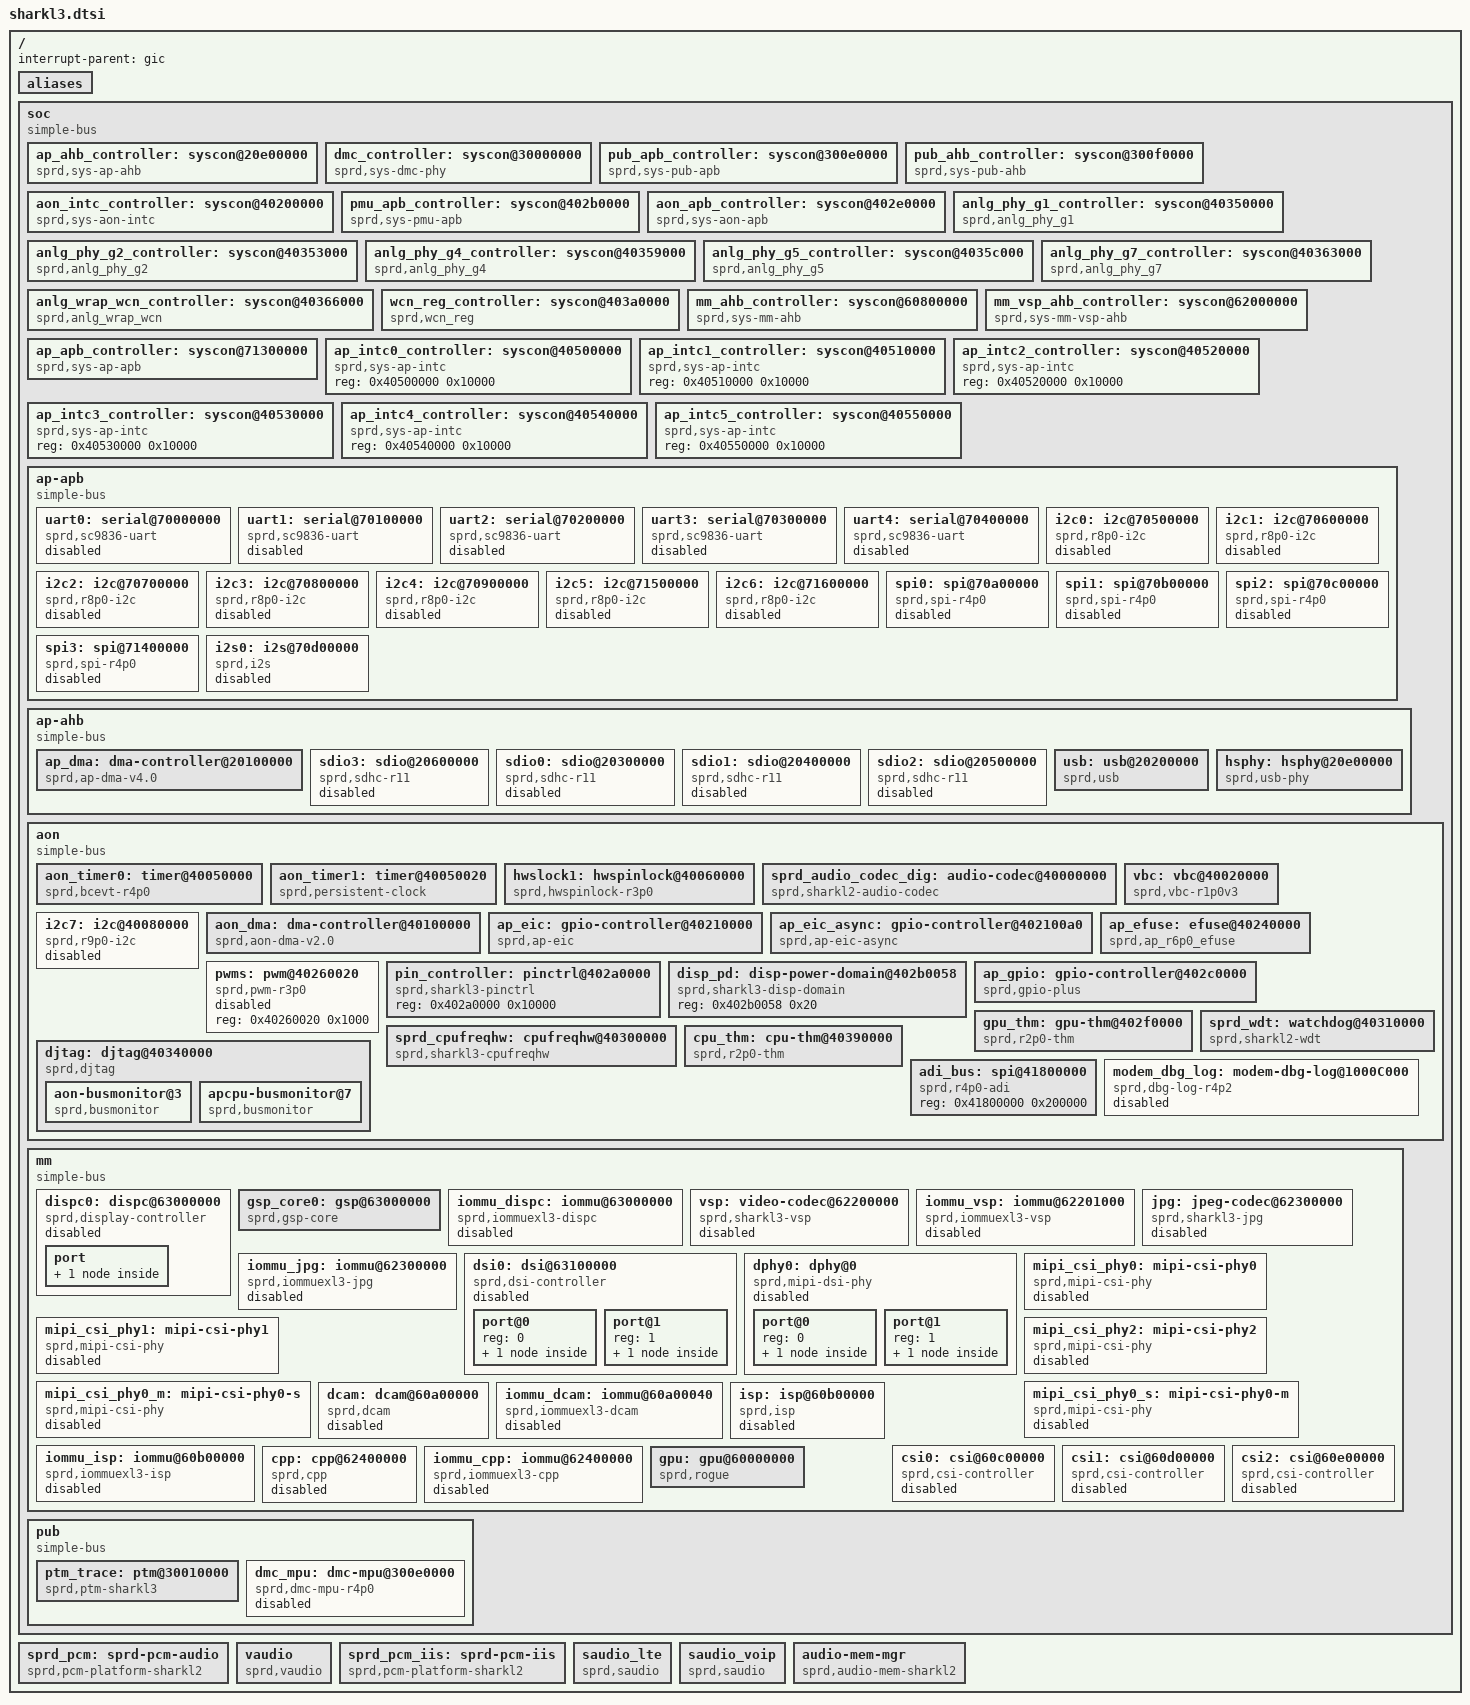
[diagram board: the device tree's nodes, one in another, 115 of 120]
/*
 * Spreadtrum Sharkl3 platform DTS file
 *
 * Copyright (C) 2017, Spreadtrum Communications Inc.
 *
 * This file is licensed under a dual GPLv2 or X11 license.
 */

#include <dt-bindings/debug/busmonitor.h>
#include <dt-bindings/interrupt-controller/arm-gic.h>
#include <dt-bindings/dmc_mpu/sharkl3_dmc_mpu.h>

/ {
	interrupt-parent = <&gic>;
	#address-cells = <1>;
	#size-cells = <1>;

	aliases {
		serial0 = &uart0;
		serial1 = &uart1;
		serial2 = &uart2;
		serial3 = &uart3;
		i2c0 = &i2c0;
		i2c1 = &i2c1;
		i2c2 = &i2c2;
		i2c3 = &i2c3;
		i2c4 = &i2c4;
		i2c5 = &i2c5;
		i2c6 = &i2c6;
		i2c7 = &i2c7;
		spi0 = &spi0;
		spi1 = &spi1;
		spi2 = &spi2;
		spi3 = &spi3;
		hwspinlock1 = &hwslock1;
		thm-sensor0 = &gpu_thm;
		thm-sensor1 = &cpu_thm;
	};

	soc: soc {
		compatible = "simple-bus";
		#address-cells = <1>;
		#size-cells = <1>;
		ranges;

		ap_ahb_controller: syscon@20e00000 {
			compatible = "sprd,sys-ap-ahb", "syscon";
			reg = <0x20e00000 0x10000>;
			hwlocks = <&hwslock1 1>;
			hwlock-names = "syscon";
		};

		dmc_controller: syscon@30000000 {
			compatible = "sprd,sys-dmc-phy", "syscon";
			reg = <0x30000000 0x400>;
			sprd,sizel_off = <0x1c4>;
			sprd,sizeh_off = <0x1c8>;
		};

		pub_apb_controller: syscon@300e0000 {
			compatible = "sprd,sys-pub-apb", "syscon";
			reg = <0x300e0000 0x10000>;
			hwlocks = <&hwslock1 1>;
			hwlock-names = "syscon";
		};

		pub_ahb_controller: syscon@300f0000 {
			compatible = "sprd,sys-pub-ahb", "syscon";
			reg = <0x300f0000 0x10000>;
			hwlocks = <&hwslock1 1>;
			hwlock-names = "syscon";
		};

		aon_intc_controller: syscon@40200000 {
			compatible = "sprd,sys-aon-intc", "syscon";
			reg = <0x40200000 0x10000>;
			hwlocks = <&hwslock1 1>;
			hwlock-names = "syscon";
		};

		pmu_apb_controller: syscon@402b0000 {
			compatible = "sprd,sys-pmu-apb", "syscon";
			reg = <0x402b0000 0x10000>;
			hwlocks = <&hwslock1 1>;
			hwlock-names = "syscon";
		};

		aon_apb_controller: syscon@402e0000 {
			compatible = "sprd,sys-aon-apb", "syscon";
			reg = <0x402e0000 0x10000>;
			hwlocks = <&hwslock1 1>;
			hwlock-names = "syscon";
		};

		anlg_phy_g1_controller: syscon@40350000 {
			compatible = "sprd,anlg_phy_g1", "syscon";
			reg = <0x40350000 0x3000>;
			hwlocks = <&hwslock1 1>;
			hwlock-names = "syscon";
		};

		anlg_phy_g2_controller: syscon@40353000 {
			compatible = "sprd,anlg_phy_g2", "syscon";
			reg = <0x40353000 0x6000>;
			hwlocks = <&hwslock1 1>;
			hwlock-names = "syscon";
		};

		anlg_phy_g4_controller: syscon@40359000 {
			compatible = "sprd,anlg_phy_g4", "syscon";
			reg = <0x40359000 0x3000>;
			hwlocks = <&hwslock1 1>;
			hwlock-names = "syscon";
		};

		anlg_phy_g5_controller: syscon@4035c000 {
			compatible = "sprd,anlg_phy_g5", "syscon";
			reg = <0x4035c000 0x3000>;
			hwlocks = <&hwslock1 1>;
			hwlock-names = "syscon";
		};

		anlg_phy_g7_controller: syscon@40363000 {
			compatible = "sprd,anlg_phy_g7", "syscon";
			reg = <0x40363000 0x3000>;
			hwlocks = <&hwslock1 1>;
			hwlock-names = "syscon";
		};

		anlg_wrap_wcn_controller: syscon@40366000 {
			compatible = "sprd,anlg_wrap_wcn", "syscon";
			reg = <0x40366000 0x3000>;
			hwlocks = <&hwslock1 1>;
			hwlock-names = "syscon";
		};

		wcn_reg_controller: syscon@403a0000 {
			compatible = "sprd,wcn_reg", "syscon";
			reg = <0x403a0000 0x10000>;
			hwlocks = <&hwslock1 1>;
			hwlock-names = "syscon";
		};

		mm_ahb_controller: syscon@60800000 {
			compatible = "sprd,sys-mm-ahb", "syscon";
			reg = <0x60800000 0x10000>;
			hwlocks = <&hwslock1 1>;
			hwlock-names = "syscon";
		};

		mm_vsp_ahb_controller: syscon@62000000 {
			compatible = "sprd,sys-mm-vsp-ahb", "syscon";
			reg = <0x62000000 0x10000>;
			hwlocks = <&hwslock1 1>;
			hwlock-names = "syscon";
		};

		ap_apb_controller: syscon@71300000 {
			compatible = "sprd,sys-ap-apb", "syscon";
			reg = <0x71300000 0x40000>;
			hwlocks = <&hwslock1 1>;
			hwlock-names = "syscon";
		};

		ap_intc0_controller: syscon@40500000 {
			compatible = "sprd,sys-ap-intc", "syscon";
			reg = <0x40500000 0x10000>;
		};

		ap_intc1_controller: syscon@40510000 {
			compatible = "sprd,sys-ap-intc", "syscon";
			reg = <0x40510000 0x10000>;
		};

		ap_intc2_controller: syscon@40520000 {
			compatible = "sprd,sys-ap-intc", "syscon";
			reg = <0x40520000 0x10000>;
		};

		ap_intc3_controller: syscon@40530000 {
			compatible = "sprd,sys-ap-intc", "syscon";
			reg = <0x40530000 0x10000>;
		};

		ap_intc4_controller: syscon@40540000 {
			compatible = "sprd,sys-ap-intc", "syscon";
			reg = <0x40540000 0x10000>;
		};

		ap_intc5_controller: syscon@40550000 {
			compatible = "sprd,sys-ap-intc", "syscon";
			reg = <0x40550000 0x10000>;
		};

		ap-apb {
			compatible = "simple-bus";
			#address-cells = <1>;
			#size-cells = <1>;
			ranges;

			uart0: serial@70000000 {
				compatible = "sprd,sc9836-uart",
					     "sprd,sc9838-uart";
				reg = <0x70000000 0x100>;
				interrupts = <GIC_SPI 2 IRQ_TYPE_LEVEL_HIGH>;
				clock-names = "uart", "source", "enable";
				status = "disabled";
			};

			uart1: serial@70100000 {
				compatible = "sprd,sc9836-uart",
					     "sprd,sc9838-uart";
				reg = <0x70100000 0x100>;
				interrupts = <GIC_SPI 3 IRQ_TYPE_LEVEL_HIGH>;
				clock-names = "uart", "source", "enable";
				status = "disabled";
			};

			uart2: serial@70200000 {
				compatible = "sprd,sc9836-uart",
					     "sprd,sc9838-uart";
				reg = <0x70200000 0x100>;
				interrupts = <GIC_SPI 4 IRQ_TYPE_LEVEL_HIGH>;
				clock-names = "uart", "source", "enable";
				status = "disabled";
			};

			uart3: serial@70300000 {
				compatible = "sprd,sc9836-uart",
					     "sprd,sc9838-uart";
				reg = <0x70300000 0x100>;
				interrupts = <GIC_SPI 5 IRQ_TYPE_LEVEL_HIGH>;
				clock-names = "uart", "source", "enable";
				status = "disabled";
			};

			uart4: serial@70400000 {
				compatible = "sprd,sc9836-uart",
					     "sprd,sc9838-uart";
				reg = <0x70400000 0x100>;
				interrupts = <GIC_SPI 6 IRQ_TYPE_LEVEL_HIGH>;
				clock-names = "uart", "source", "enable";
				status = "disabled";
			};

			i2c0: i2c@70500000 {
				compatible = "sprd,r8p0-i2c";
				reg = <0x70500000 0x1000>;
				interrupts = <GIC_SPI 11 IRQ_TYPE_LEVEL_HIGH>;
				clock-names = "enable","i2c", "source";
				clock-frequency = <100000>;
				#address-cells = <1>;
				#size-cells = <0>;
				status = "disabled";
			};

			i2c1: i2c@70600000 {
				compatible = "sprd,r8p0-i2c";
				reg = <0x70600000 0x1000>;
				interrupts = <GIC_SPI 12 IRQ_TYPE_LEVEL_HIGH>;
				clock-names = "enable","i2c", "source";
				clock-frequency = <100000>;
				#address-cells = <1>;
				#size-cells = <0>;
				status = "disabled";
			};

			i2c2: i2c@70700000 {
				compatible = "sprd,r8p0-i2c";
				reg = <0x70700000 0x1000>;
				interrupts = <GIC_SPI 13 IRQ_TYPE_LEVEL_HIGH>;
				clock-names = "enable","i2c", "source";
				clock-frequency = <100000>;
				#address-cells = <1>;
				#size-cells = <0>;
				status = "disabled";
			};

			i2c3: i2c@70800000 {
				compatible = "sprd,r8p0-i2c";
				reg = <0x70800000 0x1000>;
				interrupts = <GIC_SPI 14 IRQ_TYPE_LEVEL_HIGH>;
				clock-names = "enable","i2c", "source";
				clock-frequency = <400000>;
				#address-cells = <1>;
				#size-cells = <0>;
				status = "disabled";
			};

			i2c4: i2c@70900000 {
				compatible = "sprd,r8p0-i2c";
				reg = <0x70900000 0x1000>;
				interrupts = <GIC_SPI 15 IRQ_TYPE_LEVEL_HIGH>;
				clock-names = "enable","i2c", "source";
				clock-frequency = <100000>;
				#address-cells = <1>;
				#size-cells = <0>;
				status = "disabled";
			};

			i2c5: i2c@71500000 {
				compatible = "sprd,r8p0-i2c";
				reg = <0x71500000 0x1000>;
				interrupts = <GIC_SPI 116 IRQ_TYPE_LEVEL_HIGH>;
				clock-names = "enable","i2c", "source";
				clock-frequency = <100000>;
				#address-cells = <1>;
				#size-cells = <0>;
				status = "disabled";
			};

			i2c6: i2c@71600000 {
				compatible = "sprd,r8p0-i2c";
				reg = <0x71600000 0x1000>;
				interrupts = <GIC_SPI 117 IRQ_TYPE_LEVEL_HIGH>;
				clock-names = "enable","i2c", "source";
				clock-frequency = <100000>;
				#address-cells = <1>;
				#size-cells = <0>;
				status = "disabled";
			};

			spi0: spi@70a00000{
				compatible = "sprd,spi-r4p0";
				reg = <0x70a00000 0x1000>;
				interrupts = <GIC_SPI 7 IRQ_TYPE_LEVEL_HIGH>;
				clock-names = "enable", "spi", "source";
				sprd,dma-mode = <0>;
				sprd,rxtx-dma = <11 12>;
				dma-names = "rx_chn", "tx_chn";
				#address-cells = <1>;
				#size-cells = <0>;
				status = "disabled";
			};

			spi1: spi@70b00000{
				compatible = "sprd,spi-r4p0";
				reg = <0x70b00000 0x1000>;
				interrupts = <GIC_SPI 8 IRQ_TYPE_LEVEL_HIGH>;
				clock-names = "enable", "spi", "source";
				sprd,dma-mode = <0>;
				sprd,rxtx-dma = <13 14>;
				dma-names = "rx_chn", "tx_chn";
				#address-cells = <1>;
				#size-cells = <0>;
				status = "disabled";
			};

			spi2: spi@70c00000{
				compatible = "sprd,spi-r4p0";
				reg = <0x70c00000 0x1000>;
				interrupts = <GIC_SPI 9 IRQ_TYPE_LEVEL_HIGH>;
				clock-names = "enable", "spi", "source";
				sprd,dma-mode = <0>;
				sprd,rxtx-dma = <15 16>;
				dma-names = "rx_chn", "tx_chn";
				#address-cells = <1>;
				#size-cells = <0>;
				status = "disabled";
			};

			spi3: spi@71400000{
				compatible = "sprd,spi-r4p0";
				reg = <0x71400000 0x1000>;
				interrupts = <GIC_SPI 19 IRQ_TYPE_LEVEL_HIGH>;
				clock-names = "enable", "spi", "source";
				sprd,dma-mode = <0>;
				sprd,rxtx-dma = <27 28>;
				dma-names = "rx_chn", "tx_chn";
				#address-cells = <1>;
				#size-cells = <0>;
				status = "disabled";
			};

			i2s0: i2s@70d00000 {
				compatible = "sprd,i2s";
				reg = <0x70d00000 0x100000>;
				sprd,dai_name = "i2s_bt_sco0";
				sprd,hw_port = <0>;
				sprd,syscon-ap-apb = <&ap_apb_controller>;
				#sound-dai-cells = <0>;
				status = "disable";
			};
		};

		ap-ahb {
			compatible = "simple-bus";
			#address-cells = <1>;
			#size-cells = <1>;
			ranges;

			ap_dma: dma-controller@20100000 {
				compatible = "sprd,ap-dma-v4.0";
				reg = <0x20100000 0x4000>;
				interrupts = <GIC_SPI 50 IRQ_TYPE_LEVEL_HIGH>;
				#dma-cells = <1>;
				#dma-channels = <28>;
				sprd,full-type-offset = <0>;
				sprd,syscon-dma-glb = <&ap_ahb_controller>;
				clock-names = "enable";
				clocks = <&clk_ap_ahb_gates0 5>;
			};

			sdio3: sdio@20600000 {
				compatible = "sprd,sdhc-r11";
				reg = <0x20600000 0x1000>;
				interrupts = <GIC_SPI 60 IRQ_TYPE_LEVEL_HIGH>;
				status = "disabled";
			};

			sdio0: sdio@20300000 {
				compatible = "sprd,sdhc-r11";
				reg = <0x20300000 0x1000>;
				interrupts = <GIC_SPI 57 IRQ_TYPE_LEVEL_HIGH>;
				status = "disabled";
			};

			sdio1: sdio@20400000 {
				compatible = "sprd,sdhc-r11";
				reg = <0x20400000 0x1000>;
				interrupts = <GIC_SPI 58 IRQ_TYPE_LEVEL_HIGH>;
				status = "disabled";
			};

			sdio2: sdio@20500000 {
				compatible = "sprd,sdhc-r11";
				reg = <0x20500000 0x1000>;
				interrupts = <GIC_SPI 59 IRQ_TYPE_LEVEL_HIGH>;
				status = "disabled";
			};

			usb: usb@20200000 {
				compatible = "sprd,usb";
				reg = <0x20200000 0x2000>;
				interrupts = <GIC_SPI 55 IRQ_TYPE_LEVEL_HIGH>;
				interrupt-names = "mc";
				clocks = <&clk_ap_ahb_gates0 4>;
				clock-names = "core_clk";
				phy-type = "usb20_sprd_phy";
				usb-phy = <&hsphy>;
				phy-names = "usb";
				dr-mode = "peripheral";
			};

			hsphy: hsphy@20e00000 {
				compatible = "sprd,usb-phy";
				reg = <0x20e00000 0x3030>;
				reg-names = "phy_glb_regs";
				sprd,syscon-enable = <&aon_apb_controller>;
				sprd,syscon-apahb = <&ap_ahb_controller>;
				sprd,syscon-anag4 = <&anlg_phy_g4_controller>;
				sprd,vdd-voltage = <3300000>;
				#phy-cells = <0>;
			};
		};

		aon {
			compatible = "simple-bus";
			#address-cells = <1>;
			#size-cells = <1>;
			ranges;

			aon_timer0: timer@40050000 {
				compatible = "sprd,bcevt-r4p0";
				reg = <0x40050000 0x14>;
				interrupts = <GIC_SPI 27 IRQ_TYPE_LEVEL_HIGH>;
				clock-frequency = <32768>;
			};

			aon_timer1: timer@40050020 {
				compatible = "sprd,persistent-clock";
				reg = <0x40050020 0x14>;
				interrupts = <GIC_SPI 28 IRQ_TYPE_LEVEL_HIGH>;
				clock-frequency = <32768>;
			};

			hwslock1: hwspinlock@40060000{
				compatible  = "sprd,hwspinlock-r3p0";
				reg = <0x40060000 0x1000>;
				#hwlock-cells = <1>;
				hwlocks-base = <0>;
				hwlocks-num = <32>;
				clock-names = "enable";
				clocks = <&clk_aon_apb_gates0 22>;
				sprd,axi-id;
			};

			sprd_audio_codec_dig: audio-codec@40000000 {
				compatible = "sprd,sharkl2-audio-codec";
				reg = <0x40000000 0x2000>;
				interrupts = <GIC_SPI 20  IRQ_TYPE_NONE>;
				sprd,syscon-aon-apb = <&aon_apb_controller>;
				/* sharkle use g6 */
				sprd,anlg-phy-g-syscon = <&anlg_phy_g7_controller>;
			};

			vbc: vbc@40020000 {
				compatible = "sprd,vbc-r1p0v3";
				#sound-dai-cells = <1>;
				reg = <0x40020000 0x10000>;
				sprd,clk-stable = <0x402d0060 0x4>;
				sprd,syscon-aon-apb = <&aon_apb_controller>;
				sprd,syscon-pmu-apb = <&pmu_apb_controller>;
				sprd,dynamic-eq-support = <0>;
				 /* da01, ad01, ad23 */
				sprd,vbc-iis-lr-invert = <0 1 1>;
				/*0: aon dma, 1: ap dma
				 * da01, da23, ad01, ad23
				 */
				sprd,vbc-use-dma-type = <0 0 0 0>;
				sprd,vbc-use-ad01-only = <1>;
				sprd,iis_bt_fm_loop = <3 4>;
				pinctrl-names =
				/* interface 0 */
				"vbc_iis1_0", "ap_iis0_0", "ap_iis1_0", "tgdsp_iis0_0",
				"tgdsp_iis1_0", "pubcp_iis0_0",
				/* interface 3 */
				"vbc_iis1_3", "ap_iis0_3", "tgdsp_iis0_3",
				"tgdsp_iis1_3", "pubcp_iis0_3","wcn_iis0_3",
				/* interface 4 */
				"vbc_iis1_4", "ap_iis0_4", "tgdsp_iis0_4",
				"tgdsp_iis1_4", "pubcp_iis0_4", "wcn_iis0_4",
				/* interface loop */
				"iis_bt_fm_loop_3_4_enable",
				"iis_bt_fm_loop_3_4_disable";
				/* infterface 0 */
				pinctrl-0 = <&vbc_iis1_0>;
				pinctrl-1 = <&ap_iis0_0>;
				pinctrl-2 = <&ap_iis1_0>;
				pinctrl-3 = <&tgdsp_iis0_0>;
				pinctrl-4 = <&tgdsp_iis1_0>;
				pinctrl-5 = <&pubcp_iis0_0>;
				/* infterface 3 */
				pinctrl-6 = <&vbc_iis1_3>;
				pinctrl-7 = <&ap_iis0_3>;
				pinctrl-8 = <&tgdsp_iis0_3>;
				pinctrl-9 = <&tgdsp_iis1_3>;
				pinctrl-10 = <&pubcp_iis0_3>;
				pinctrl-11 = <&wcn_iis0_3>;
				/* infterface 4 */
				pinctrl-12 = <&vbc_iis1_4>;
				pinctrl-13 = <&ap_iis0_4>;
				pinctrl-14 = <&tgdsp_iis0_4>;
				pinctrl-15 = <&tgdsp_iis1_4>;
				pinctrl-16 = <&pubcp_iis0_4>;
				pinctrl-17 = <&wcn_iis0_4>;
				/* interface loop */
				pinctrl-18 = <&iis_loop_3_4_enable>;
				pinctrl-19 = <&iis_loop_3_4_disable>;
			};

			i2c7: i2c@40080000 {
				compatible = "sprd,r9p0-i2c";
				reg = <0x40080000 0x1000>;
				interrupts = <GIC_SPI 34 IRQ_TYPE_LEVEL_HIGH>;
				clock-names = "enable","i2c", "source",
					"clk_hw_i2c";
				clock-frequency = <100000>;
				#address-cells = <1>;
				#size-cells = <0>;
				status = "disabled";
			};

			aon_dma: dma-controller@40100000 {
				compatible = "sprd,aon-dma-v2.0";
				reg = <0x40100000 0x4000>;
				#dma-cells = <1>;
				#dma-channels = <9>;
				sprd,full-type-offset = <0>;
				sprd,syscon-dma-glb = <&aon_apb_controller>;
				clock-names = "enable";
				clocks = <&clk_aon_apb_gates1 22>;
			};

			ap_eic: gpio-controller@40210000 {
				compatible = "sprd,ap-eic";
				reg =	<0x40210000 0x80>,
					<0x40370000 0x80>;
				gpio-controller;
				#gpio-cells = <2>;
				sprd,gpiobase = <288>;
				sprd,ngpios = <32>;
				interrupt-controller;
				#interrupt-cells = <2>;
				interrupts = <GIC_SPI 37 IRQ_TYPE_LEVEL_HIGH>;
			};

			ap_eic_async: gpio-controller@402100a0 {
				compatible = "sprd,ap-eic-async";
				reg =	<0x402100a0 0x40>,
					<0x403700a0 0x40>;
				gpio-controller;
				#gpio-cells = <2>;
				sprd,gpiobase = <336>;
				sprd,ngpios = <32>;
				interrupt-controller;
				#interrupt-cells = <2>;
				interrupts = <GIC_SPI 37 IRQ_TYPE_LEVEL_HIGH>;
			};

			ap_efuse: efuse@40240000 {
				compatible = "sprd,ap_r6p0_efuse";
				sprd,syscon-enable = <&aon_apb_controller>;
				reg = <0x40240000 0x10000>;
				clock-names = "enable";
				clocks = <&clk_aon_apb_gates0 13>;
				sprd,uid-start= <95 0>;
				sprd,uid-end= <94 0>;
				sprd,block-start= <36>;
				sprd,block-num = <10>;
				sprd,block-width = <32>;
				hwlocks = <&hwslock1 8>;
				hwlock-names = "ap_efuse";
			};

			pwms: pwm@40260020 {
				#pwm-cells = <2>;
				compatible = "sprd,pwm-r3p0";
				reg = <0x40260020 0x1000>;
				status = "disabled";
			};

			pin_controller: pinctrl@402a0000 {
				compatible = "sprd,sharkl3-pinctrl";
				reg = <0x402a0000 0x10000>;
			};

			disp_pd: disp-power-domain@402b0058 {
				compatible = "sprd,sharkl3-disp-domain";
				reg = <0x402b0058 0x20>;
				#power-domain-cells = <0>;
			};

			ap_gpio: gpio-controller@402c0000 {
				compatible = "sprd,gpio-plus";
				reg = <0x402c0000 0x1000>;
				gpio-controller;
				#gpio-cells = <2>;
				sprd,gpiobase = <0>;
				sprd,ngpios = <256>;
				interrupt-controller;
				#interrupt-cells = <2>;
				interrupts = <GIC_SPI 130 IRQ_TYPE_LEVEL_HIGH>;
			};

			gpu_thm: gpu-thm@402f0000 {
				compatible = "sprd,r2p0-thm";
				sprd,syscon-enable = <&aon_apb_controller>;
				reg = <0x402f0000 0x10000>;
				clock-names = "enable";
				clocks = <&clk_aon_apb_gates1 1>;
				#thermal-sensor-cells = <1>;
				power-down = <0>;
				otp-temp = <120000>;
				algor_ver = <2>;
				cal_k = <903>;
				cal_b = <71290>;
				cal_efuse_blk = <44>;
				cal_efuse_bit = <9>;
				ratio_off_bit = <2>;
				ratio_sign_bit = <1>;
			};

			sprd_cpufreqhw: cpufreqhw@40300000 {
				compatible = "sprd,sharkl3-cpufreqhw";
				sprd,syscon-enable = <&aon_apb_controller>;
				sprd,anlg-phy-g4-ctrl = <&anlg_phy_g4_controller>;
				reg = <0x40300000 0x1000>;
				interrupts = <GIC_SPI 121 IRQ_TYPE_LEVEL_HIGH>;
			 };

			sprd_wdt: watchdog@40310000 {
				compatible = "sprd,sharkl2-wdt";
				reg = <0x40310000 0x1000>;
				interrupts = <GIC_SPI 124 IRQ_TYPE_LEVEL_HIGH>;
				clock-names = "enable", "rtc_enable";
				sprd,wdt-enable = <&aon_apb_controller>;
			};

			djtag: djtag@40340000 {
				compatible = "sprd,djtag";
				reg = <0x40340000 0x1000>,
					<0x402e0000 0x10000>;
				reg-names = "djtag", "glb";
				clock-names = "enable", "tck";
				clocks = <&clk_aon_apb_gates1 20>,
					<&clk_aon_apb_gates1 11>;
				hwlocks = <&hwslock1 10>;
				hwlock-names = "djtag";
				sprd,djtag-notck;
				#address-cells = <1>;
				#size-cells = <0>;

				aon-busmonitor@3{
					compatible  = "sprd,busmonitor";
					interrupts = <GIC_SPI 92
						IRQ_TYPE_LEVEL_HIGH>;
					reg = <0x3>;
					sprd,bm-num = <7>;
					sprd,bm-name =
						"AP", "WTLCP", "PUBCP", "SP",
						"DMA", "EAXI", "WCN";
					sprd,bm-type =
						<AXI>, <AXI>, <AXI>, <AXI>,
						<AXI>, <AXI>, <AXI>;
					sprd,bm-dap = <0>, <2>, <1>, <3>,
						<4>, <5>, <9>;
					sprd,bm-config =
						<DISABLE MON_WRITE MON_INSIDE>,
						<DISABLE MON_WRITE MON_INSIDE>,
						<DISABLE MON_WRITE MON_INSIDE>,
						<DISABLE MON_WRITE MON_INSIDE>,
						<DISABLE MON_WRITE MON_INSIDE>,
						<DISABLE MON_WRITE MON_INSIDE>,
						<DISABLE MON_WRITE MON_INSIDE>;
					sprd,bm-id =
						<DISABLE 0 AXIID>,
						<DISABLE 0 AXIID>,
						<DISABLE 0 AXIID>,
						<DISABLE 0 AXIID>,
						<DISABLE 0 AXIID>,
						<DISABLE 0 AXIID>,
						<DISABLE 0 AXIID>;
					sprd,bm-ranges =
						<0 0>, <0 0>, <0 0>,
						<0 0>, <0 0>, <0 0>,
						<0 0>;
				};

				apcpu-busmonitor@7{
					compatible  = "sprd,busmonitor";
					interrupts = <GIC_SPI 87
						IRQ_TYPE_LEVEL_HIGH>;
					reg = <0x7>;
					sprd,bm-num = <2>;
					sprd,bm-name = "ACE", "AP";
					sprd,bm-type = <AXI>, <AXI>;
					sprd,bm-dap = <1>, <2>;
					sprd,bm-config =
						<DISABLE MON_WRITE MON_INSIDE>,
						<DISABLE MON_WRITE MON_INSIDE>;
					sprd,bm-id =
						<DISABLE 0 AXIID>,
						<DISABLE 0 AXIID>;
					sprd,bm-ranges = <0 0>, <0 0>;
				};
			};

			cpu_thm: cpu-thm@40390000 {
				compatible = "sprd,r2p0-thm";
				sprd,syscon-enable = <&aon_apb_controller>;
				reg = <0x40390000 0x10000>;
				clock-names = "enable";
				clocks = <&clk_aon_apb_gates1 1>;
				#thermal-sensor-cells = <1>;
				power-down = <0>;
				otp-temp = <120000>;
				algor_ver = <1>;
				cal_k = <903>;
				cal_b = <71290>;
				cal_efuse_blk = <44>;
				cal_efuse_bit = <24>;
				ratio_off_bit = <17>;
				ratio_sign_bit = <16>;
			};

			adi_bus: spi@41800000 {
				compatible = "sprd,r4p0-adi";
				reg = <0x41800000 0x200000>;
				#address-cells = <1>;
				#size-cells = <0>;
			};

			modem_dbg_log: modem-dbg-log@1000C000 {
				compatible = "sprd,dbg-log-r4p2";
				reg = <0x1000C000 0x4000>;
				sprd,syscon-aon-apb = <&aon_apb_controller>;
				sprd,syscon-dsi-apb = <&anlg_phy_g1_controller>;
				sprd,syscon-pll-apb = <&anlg_phy_g2_controller>;
				sprd,ch_num = <6>;
				sprd,ch_str = "TRAINING", "WTL", "MDAR", "TPIU", "DBUS", "WCN";
				sprd,ch_sel = <15 1 0 2 3 4>;
				sprd,dcfix = <1>;
				sprd,mm = <1>;
				status = "disabled";
			};

		};

		mm {
			compatible = "simple-bus";
			#address-cells = <1>;
			#size-cells = <1>;
			ranges;

			dispc0: dispc@63000000 {
				compatible = "sprd,display-controller";
				reg = <0x63000000 0x1000>;
				interrupts = <GIC_SPI 46 IRQ_TYPE_LEVEL_HIGH>;
				iommus = <&iommu_dispc>;
				power-domains = <&disp_pd>;
				status = "disabled";

				sprd,ip = "dpu-r2p0";
				sprd,soc = "sharkl3";

				sprd,syscon-aon-apb = <&aon_apb_controller>;

				/* output port */
				port {
					dispc0_out: endpoint@0 {
						remote-endpoint = <&dsi0_in>;
					};
				};
			};

			gsp_core0: gsp@63000000 {
				compatible = "sprd,gsp-core";
				reg = <0x63000000  0x2000>;
				core-id = <0>;
				kcfg-num = <16>;
				interrupts = <GIC_SPI 51 IRQ_TYPE_LEVEL_HIGH>;
				iommus = <&iommu_dispc>;
			};

			iommu_dispc: iommu@63000000 {
				compatible = "sprd,iommuexl3-dispc";
				reg = <0x63000000 0x800>,
				      <0x63000800 0x80>,
				      <0x30000000 0x10000000>;
				reg_name = "mmu_interrupt_reg","mmu_reg",
					   "iova pool";
				status = "disabled";
				#iommu-cells = <0>;
			};

			vsp: video-codec@62200000{
				compatible = "sprd,sharkl3-vsp";
				reg = <0x62200000 0xc000>;
				interrupts = <GIC_SPI 43 IRQ_TYPE_LEVEL_HIGH>;
				sprd,syscon-pmu-apb = <&pmu_apb_controller>;
				sprd,syscon-aon-apb = <&aon_apb_controller>;
				sprd,syscon-mm-ahb = <&mm_vsp_ahb_controller>;
				iommus = <&iommu_vsp>;
				status = "disabled";
			};

			iommu_vsp: iommu@62201000 {
				compatible = "sprd,iommuexl3-vsp";
				reg = <0x62201000 0xb000>,
				      <0x62200000 0x80>,
				      <0x20000000 0x10000000>;
				reg_name = "mmu_interrupt_reg","mmu_reg",
					   "iova pool";
				status = "disabled";
				#iommu-cells = <0>;
			};

			jpg: jpeg-codec@62300000{
				compatible = "sprd,sharkl3-jpg";
				reg = <0x62300000 0x8000>;
				interrupts = <GIC_SPI 42 IRQ_TYPE_LEVEL_HIGH>;
				sprd,syscon-pmu-apb = <&pmu_apb_controller>;
				sprd,syscon-aon-apb = <&aon_apb_controller>;
				sprd,syscon-mm-ahb = <&mm_vsp_ahb_controller>;
				iommus = <&iommu_jpg>;
				status = "disabled";
			};

			iommu_jpg: iommu@62300000 {
				compatible = "sprd,iommuexl3-jpg";
				reg = <0x62300000 0x300>,
				      <0x62300300 0x400>,
				      <0x70000000 0x10000000>;
				reg_name = "mmu_interrupt_reg","mmu_reg",
					   "iova pool";
				status = "disabled";
				#iommu-cells = <0>;
			};

			dsi0: dsi@63100000 {
				compatible = "sprd,dsi-controller";
				#address-cells = <1>;
				#size-cells = <0>;
				reg = <0x63100000 0x1000>;
				interrupts = <GIC_SPI 48 IRQ_TYPE_LEVEL_HIGH>,
					<GIC_SPI 49 IRQ_TYPE_LEVEL_HIGH>;
				power-domains = <&disp_pd>;
				status = "disabled";

				sprd,ip = "sprd,dsi-ctrl-r1p0";
				sprd,soc = "sharkl3";

				sprd,syscon-aon-apb = <&aon_apb_controller>;

				/* output port */
				port@0 {
					reg = <0>;
					dsi0_out: endpoint {
						remote-endpoint = <&dphy0_in>;
					};
				};

				/* input port */
				port@1 {
					reg = <1>;
					dsi0_in: endpoint {
						remote-endpoint = <&dispc0_out>;
					};
				};
			};

			dphy0: dphy@0 {
				compatible = "sprd,mipi-dsi-phy";
				#address-cells = <1>;
				#size-cells = <0>;
				reg = <0x63100000 0x1000>;
				status = "disabled";

				sprd,ip = "sprd,megacores-sharkle";
				sprd,soc = "sharkl3";

				sprd,syscon-aon-apb = <&aon_apb_controller>;

				/* output port */
				port@0 {
					reg = <0>;
					dphy0_out: endpoint {
						remote-endpoint = <&panel_in>;
					};
				};

				/* input port*/
				port@1 {
					reg = <1>;
					dphy0_in: endpoint {
						remote-endpoint = <&dsi0_out>;
					};
				};
			};

			mipi_csi_phy0: mipi-csi-phy0 {
				compatible = "sprd,mipi-csi-phy";
				sprd,phyid = <0>;
				sprd,phyname = "2p2";
				status = "disabled";
			};

			mipi_csi_phy1: mipi-csi-phy1 {
				compatible = "sprd,mipi-csi-phy";
				sprd,phyid = <1>;
				sprd,phyname = "4lane";
				status = "disabled";
			};

			mipi_csi_phy2: mipi-csi-phy2 {
				compatible = "sprd,mipi-csi-phy";
				sprd,phyid = <2>;
				sprd,phyname = "2lane";
				status = "disabled";
			};

			mipi_csi_phy0_m: mipi-csi-phy0-s {
				compatible = "sprd,mipi-csi-phy";
				sprd,phyid = <3>;
				sprd,phyname = "2p2_m";
				status = "disabled";
			};

			mipi_csi_phy0_s: mipi-csi-phy0-m {
				compatible = "sprd,mipi-csi-phy";
				sprd,phyid = <4>;
				sprd,phyname = "2p2_s";
				status = "disabled";
			};

			dcam: dcam@60a00000 {
				compatible = "sprd,dcam";
				reg = <0x60a00000 0x1000>,
					<0x60a01000 0x1000>,
					<0x60a02000 0x1000>,
					<0x60a03000 0x1000>;
				reg_name = "dcam0_reg","dcam1_reg",
					"dcam2_reg","axi_ctrl_reg";
				interrupts = <GIC_SPI 45 IRQ_TYPE_LEVEL_HIGH>,
					<GIC_SPI 158 IRQ_TYPE_LEVEL_HIGH>,
					<GIC_SPI 159 IRQ_TYPE_LEVEL_HIGH>;
				interrupts_name = "dcam0", "dcam1",
					"dcam2";
				sprd,syscon-pmu-apb = <&pmu_apb_controller>;
				sprd,aon-apb-syscon = <&aon_apb_controller>;
				sprd,cam-ahb-syscon = <&mm_ahb_controller>;
				sprd,isp = <&isp>;
				sprd,dcam-count = <3>;
				iommus = <&iommu_dcam>;
				status = "disable";
			};

			iommu_dcam: iommu@60a00040 {
				compatible = "sprd,iommuexl3-dcam";
				reg = <0x60a00000 0xc000>,
				      <0x60a0c000 0x60>,
				      <0x40000000 0x10000000>;
				reg_name = "mmu_interrupt_reg", "mmu_reg",
					   "iova pool";
				status = "disabled";
				#iommu-cells = <0>;
			};

			isp: isp@60b00000 {
				compatible = "sprd,isp";
				reg = <0x60b00000 0x100000>;
				interrupts = <GIC_SPI 44 IRQ_TYPE_LEVEL_HIGH>,
					<GIC_SPI 125 IRQ_TYPE_LEVEL_HIGH>;
				interrupts_name = "ch0", "ch1";
				sprd,aon-apb-syscon = <&aon_apb_controller>;
				sprd,cam-ahb-syscon = <&mm_ahb_controller>;
				sprd,isp-count = <1>;
				iommus = <&iommu_isp>;
				status = "disable";
			};

			iommu_isp: iommu@60b00000 {
				compatible = "sprd,iommuexl3-isp";
				/* sharkl3 isp need pagetalbe size */
				reg = <0x60b00000 0xffc00>,
					<0x60bffc00 0x400>,
					<0x50000000 0x10000000>;
				reg_name = "mmu_interrupt_reg","mmu_reg",
					"iova pool";
				status = "disabled";
				#iommu-cells = <0>;
			};

			csi0: csi@60c00000 {
				compatible = "sprd,csi-controller";
				reg = <0x60c00000 0x1000>;
				interrupts = <GIC_SPI 40 IRQ_TYPE_LEVEL_HIGH>,
					<GIC_SPI 41 IRQ_TYPE_LEVEL_HIGH>;
				sprd,aon-apb-syscon = <&aon_apb_controller>;
				sprd,cam-ahb-syscon = <&mm_ahb_controller>;
				sprd,anlg_phy_g1_controller =
					<&anlg_phy_g1_controller>;
				sprd,csi-id = <0>;
				sprd,ip-version = <0x200>;
				status = "disable";
			};

			csi1: csi@60d00000 {
				compatible = "sprd,csi-controller";
				reg = <0x60d00000 0x1000>;
				interrupts = <GIC_SPI 71 IRQ_TYPE_LEVEL_HIGH>,
					<GIC_SPI 72 IRQ_TYPE_LEVEL_HIGH>;
				sprd,aon-apb-syscon = <&aon_apb_controller>;
				sprd,cam-ahb-syscon = <&mm_ahb_controller>;
				sprd,anlg_phy_g1_controller =
					<&anlg_phy_g1_controller>;
				sprd,csi-id = <1>;
				sprd,ip-version = <0x200>;
				status = "disable";
			};

			csi2: csi@60e00000 {
				compatible = "sprd,csi-controller";
				reg = <0x60e00000 0x1000>;
				interrupts = <GIC_SPI 156 IRQ_TYPE_LEVEL_HIGH>,
					<GIC_SPI 157 IRQ_TYPE_LEVEL_HIGH>;
				sprd,aon-apb-syscon = <&aon_apb_controller>;
				sprd,cam-ahb-syscon = <&mm_ahb_controller>;
				sprd,anlg_phy_g1_controller =
					<&anlg_phy_g1_controller>;
				sprd,csi-id = <1>;
				sprd,ip-version = <0x200>;
				status = "disable";
			};

			cpp: cpp@62400000 {
				compatible = "sprd,cpp";
				reg = <0x62400000 0x1000>;
				interrupts = <GIC_SPI 126 IRQ_TYPE_LEVEL_HIGH>;
				sprd,aon-apb-syscon = <&aon_apb_controller>;
				sprd,cam-ahb-syscon = <&mm_ahb_controller>;
				sprd,vsp-ahb-syscon = <&mm_vsp_ahb_controller>;
				sprd,pmu-apb-syscon = <&pmu_apb_controller>;
				iommus = <&iommu_cpp>;
				status = "disable";
			};

			iommu_cpp: iommu@62400000 {
				compatible = "sprd,iommuexl3-cpp";
				reg = <0x62400000 0x200>,
					<0x62400200 0x60>,
					<0x60000000 0x8000000>;
				reg_name = "mmu_interrupt_reg","mmu_reg",
					"iova pool";
				status = "disabled";
				#iommu-cells = <0>;
			};

			gpu: gpu@60000000 {
				compatible = "sprd,rogue";
				reg = <0x60000000 0x100000>;
				sprd,syscon-aon-apb = <&aon_apb_controller>;
				sprd,syscon-pmu-apb = <&pmu_apb_controller>;
				interrupts = <GIC_SPI 39 IRQ_TYPE_LEVEL_HIGH>;

				operating-points = <
					/* kHz    uV */
					256000    0
					384000    0
					550000    0
					>;

				sprd,dvfs-lists = <
					/* kHz  uV  idx div */
					256000  0    5   1
					384000  0    7   1
					550000  0    9   1
					>;

				sprd,dvfs-default = <0>;
				sprd,dvfs-scene-extreme = <2>;
				sprd,dvfs-scene-high = <1>;
				sprd,dvfs-scene-medium = <1>;
				sprd,dvfs-scene-low = <0>;
				sprd,dvfs-range-max = <2>;
				sprd,dvfs-range-min = <0>;
			};
		};

		pub {
			compatible = "simple-bus";
			#address-cells = <1>;
			#size-cells = <1>;
			ranges;

			ptm_trace: ptm@30010000 {
				compatible = "sprd,ptm-sharkl3";
				reg = <0x30010000 0x10000>,
					<0x10001000 0x1000>,
					<0x10003000 0x1000>,
					<0x10004000 0x1000>;
				interrupts = <GIC_SPI 86 IRQ_TYPE_LEVEL_HIGH>;
				sprd,syscon-pub-ahb = <&pub_ahb_controller>;
				sprd,funnel-port = <2>;
				sprd,ddr-chn = <8>;
				sprd,chn-name = "MM", "GPU", "DPU",
					"CPU", "AP/PUBCP", "WTLCP",
					"WCN/AON/ETR", "VSP";
			};

			dmc_mpu: dmc-mpu@300e0000 {
				compatible = "sprd,dmc-mpu-r4p0";
				reg = <0x300e0000 0x20000>;
				interrupts = <GIC_SPI 61 IRQ_TYPE_LEVEL_HIGH>;
				sprd,channel-num = <8>;
				sprd,mpu-num = <16>;
				sprd,channel-names =
					"MM", "GPU", "DPU","CPU",
					"AP/PUBCP", "WTLCP", "AON/WCN/ETR",
					"VSP", "SHARED0", "SHARED1",
					"SHARED2","SHARED3", "SHARED4",
					"SHARED5","SHARED6", "SHARED7";
				sprd,ranges = <0 0>, <0 0>, <0 0>, <0 0>,
					      <0 0>, <0 0>, <0 0>, <0 0>,
					      <0 0>, <0 0>, <0 0>, <0 0>,
					      <0 0>, <0 0>, <0 0>, <0 0>;
				sprd,chn-config =
					<DISABLE MON_INSIDE MON_WRITE>,
					<DISABLE MON_INSIDE MON_WRITE>,
					<DISABLE MON_INSIDE MON_WRITE>,
					<DISABLE MON_INSIDE MON_WRITE>,
					<DISABLE MON_INSIDE MON_WRITE>,
					<DISABLE MON_INSIDE MON_WRITE>,
					<DISABLE MON_INSIDE MON_WRITE>,
					<DISABLE MON_INSIDE MON_WRITE>,
					<DISABLE MON_INSIDE MON_WRITE>,
					<DISABLE MON_INSIDE MON_WRITE>,
					<DISABLE MON_INSIDE MON_WRITE>,
					<DISABLE MON_INSIDE MON_WRITE>,
					<DISABLE MON_INSIDE MON_WRITE>,
					<DISABLE MON_INSIDE MON_WRITE>,
					<DISABLE MON_INSIDE MON_WRITE>,
					<DISABLE MON_INSIDE MON_WRITE>;
				sprd,id-config =
					<MPUID 0 0xffff>, <MPUID 0 0xffff>,
					<MPUID 0 0xffff>, <MPUID 0 0xffff>,
					<MPUID 0 0xffff>, <MPUID 0 0xffff>,
					<MPUID 0 0xffff>, <MPUID 0 0xffff>,
					<MPUID 0 0xffff>, <MPUID 0 0xffff>,
					<MPUID 0 0xffff>, <MPUID 0 0xffff>,
					<MPUID 0 0xffff>, <MPUID 0 0xffff>,
					<MPUID 0 0xffff>, <MPUID 0 0xffff>;
				sprd,port-map = <0>, <1>, <2>, <3>, <4>,
						<5>, <6>, <7>, <0>, <0>,
						<0>, <0>, <0>, <0>, <0>,
						<0>;
				sprd,ddr-offset = <0x80000000>;
				status = "disabled";
			};
		};
	};

	sprd_pcm: sprd-pcm-audio {
		compatible = "sprd,pcm-platform-sharkl2";
		#sound-dai-cells = <0>;
		/* non-i2s playbacks use aon dma */
		/* reference dma node dma-channels proporty
		 * do not conflict with others
		 * ap_dma (29-32 for security)
		 */
		dmas = <&aon_dma 1 &aon_dma 2
				&aon_dma 3 &aon_dma 4
				&aon_dma 5 &aon_dma 6
				&aon_dma 7 &aon_dma 8
				&aon_dma 5 &aon_dma 6>;
		dma-names = "da01-l", "da01-r", "da23-l", "da23-r",
				"normal-2stage-p", "normal-2stage-c",
				"deep-2stage-p", "ad23-2stage-c",
				"ad01-l", "ad01-r";
		/* bit map for dma-2stage-usecase
		 * bit[0] == 1, normal playback
		 * bit[1] ==1, deepbuf playback
		 * bit[2] ==1, caputre
		 * other bit to do
		 */
		sprd,dma-2stage-usecase = <2>;
		sprd,node-count-2stage-level-1 = <1>;
		sprd,syscon-pmu-apb = <&pmu_apb_controller>;
		/* 0: no interrupt, 1: from arm, 2:from ap
		* note:if use arm ap should not register dma interrupt,
		* and you should register intterupt in arm code.
		*/
		sprd,dma-2stage-level-1-int-source = <1>;
	};

	vaudio: vaudio {
		compatible = "sprd,vaudio";
		#sound-dai-cells = <1>;
	};

	sprd_pcm_iis: sprd-pcm-iis {
		compatible = "sprd,pcm-platform-sharkl2";
		#sound-dai-cells = <0>;
		dmas = <&ap_dma 5 &ap_dma 6>;
		dma-names = "iis0_tx", "iis0_rx";
		sprd,dma-2stage-usecase = <2>;
		sprd,node-count-2stage-level-1 = <1>;
		sprd,syscon-pmu-apb = <&pmu_apb_controller>;
		sprd,dma-2stage-level-1-int-source = <1>;
	};

	saudio_lte{
		compatible = "sprd,saudio";
		sprd,saudio-dst-id = <5>;		/* SIPC_ID_LTE */
		sprd,ctrl_channel = <10>;		/* SMSG_CH_VBC */
		sprd,playback_channel = <11 131>; /* SMSG_CH_PLAYBACK */
		sprd,capture_channel = <12>;	/* SMSG_CH_CAPTURE */
		sprd,monitor_channel = <13>;	/*SMSG_CH_MONITOR_AUDIO */
		sprd,device = <2>;
		sprd,saudio-names = "saudiolte";
	};

	saudio_voip{
		compatible = "sprd,saudio";
		sprd,saudio-dst-id = <5>;		/* SIPC_ID_LTE */
		sprd,ctrl_channel = <14>;		/* SMSG_CH_CTRL_VOIP */
		sprd,playback_channel = <15 151>;/* SMSG_CH_PLAYBACK_VOIP */
		sprd,capture_channel = <16>;	/* SMSG_CH_CAPTURE_VOIP */
		sprd,monitor_channel = <17>;	/*SMSG_CH_MONITOR_VOIP */
		sprd,device = <2>;
		sprd,saudio-names = "saudiovoip";
	};

	audio-mem-mgr {
		compatible = "sprd,audio-mem-sharkl2";
		sprd,iram_phy_addr = <0x00002000 0xb000>;
		/* note:mmap address must paga_size align */
		sprd,iram_normal = <0x00002000 0x0>;
		sprd,iram_deepbuf = <0x00002000 0xa000>;
		sprd,iram_4arm7 = <0x0000c000 0x1000>;
	};
};

